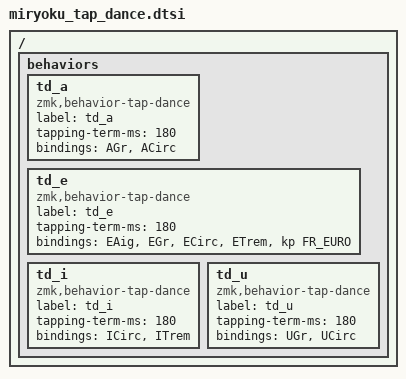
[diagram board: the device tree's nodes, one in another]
/ {
    behaviors {                
        td_a: td_a {
            compatible = "zmk,behavior-tap-dance";
            label = "td_a";
            #binding-cells = <0>;
            tapping-term-ms = <180>;
            bindings = <&AGr>, <&ACirc>;
        };

        td_e: td_e {
            compatible = "zmk,behavior-tap-dance";
            label = "td_e";
            #binding-cells = <0>;
            tapping-term-ms = <180>;
            bindings = <&EAig>, <&EGr>, <&ECirc>, <&ETrem>, <&kp FR_EURO>;
        };

        td_i: td_i {
            compatible = "zmk,behavior-tap-dance";
            label = "td_i";
            #binding-cells = <0>;
            tapping-term-ms = <180>;
            bindings = <&ICirc>, <&ITrem>;
        };  

        td_u: td_u {
            compatible = "zmk,behavior-tap-dance";
            label = "td_u";
            #binding-cells = <0>;
            tapping-term-ms = <180>;
            bindings = <&UGr>, <&UCirc>;
        };
    };
};

ZMK_UNICODE_PAIR_3_4(AGr,		KP_N1, KP_N3, KP_N3,		    KP_N0, KP_N1, KP_N9, KP_N2)	// à/À
ZMK_UNICODE_PAIR_4_4(ACirc,     KP_N0, KP_N2, KP_N2, KP_N6,     KP_N0, KP_N1, KP_N9, KP_N4) // â/Â
ZMK_UNICODE_PAIR_3_4(EAig,		KP_N1, KP_N3, KP_N0,		    KP_N0, KP_N2, KP_N0, KP_N1)	// é/É
ZMK_UNICODE_PAIR_3_4(EGr,		KP_N1, KP_N3, KP_N8,		    KP_N0, KP_N2, KP_N0, KP_N0)	// è/È
ZMK_UNICODE_PAIR_4_4(ECirc,     KP_N0, KP_N2, KP_N3, KP_N4,     KP_N0, KP_N2, KP_N0, KP_N2) // ê/Ê
ZMK_UNICODE_PAIR_4_4(ETrem,     KP_N0, KP_N2, KP_N3, KP_N5,     KP_N0, KP_N2, KP_N0, KP_N3) // ë/Ë
ZMK_UNICODE_PAIR_4_4(ICirc,     KP_N0, KP_N2, KP_N3, KP_N8,     KP_N0, KP_N2, KP_N0, KP_N6) // î/Î
ZMK_UNICODE_PAIR_4_4(ITrem,     KP_N0, KP_N2, KP_N3, KP_N9,     KP_N0, KP_N2, KP_N0, KP_N7) // ï/Ï
ZMK_UNICODE_PAIR_4_4(OCirc,     KP_N0, KP_N2, KP_N4, KP_N4,     KP_N0, KP_N2, KP_N1, KP_N2) // ô/Ô
ZMK_UNICODE_PAIR_3_4(UGr,		KP_N1, KP_N5, KP_N1,		    KP_N0, KP_N2, KP_N1, KP_N7)	// ù/Ù
ZMK_UNICODE_PAIR_3_4(UCirc,		KP_N1, KP_N5, KP_N0,		    KP_N0, KP_N2, KP_N1, KP_N9)	// ù/Ù
ZMK_UNICODE_PAIR_3_3(CCed,		KP_N1, KP_N3, KP_N5,		    KP_N1, KP_N2, KP_N8)	    // ç/Ç
